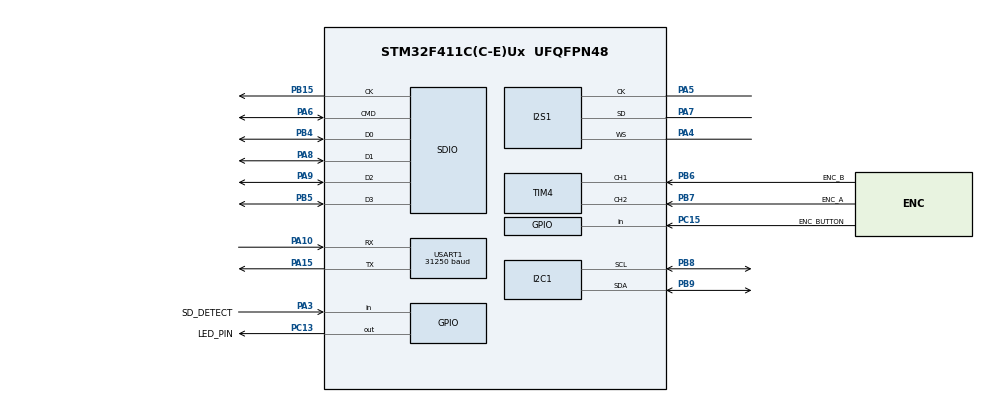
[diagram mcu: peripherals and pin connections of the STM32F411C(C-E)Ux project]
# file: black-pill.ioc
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Dma.I2C1_TX.1.Direction=DMA_MEMORY_TO_PERIPH
Dma.I2C1_TX.1.FIFOMode=DMA_FIFOMODE_DISABLE
Dma.I2C1_TX.1.Instance=DMA1_Stream1
Dma.I2C1_TX.1.MemDataAlignment=DMA_MDATAALIGN_BYTE
Dma.I2C1_TX.1.MemInc=DMA_MINC_ENABLE
Dma.I2C1_TX.1.Mode=DMA_NORMAL
Dma.I2C1_TX.1.PeriphDataAlignment=DMA_PDATAALIGN_BYTE
Dma.I2C1_TX.1.PeriphInc=DMA_PINC_DISABLE
Dma.I2C1_TX.1.Priority=DMA_PRIORITY_LOW
Dma.Request0=SPI1_TX
Dma.Request1=I2C1_TX
Dma.Request2=SDIO_RX
Dma.Request3=SDIO_TX
Dma.SDIO_RX.2.Direction=DMA_PERIPH_TO_MEMORY
Dma.SDIO_RX.2.FIFOMode=DMA_FIFOMODE_ENABLE
Dma.SDIO_RX.2.FIFOThreshold=DMA_FIFO_THRESHOLD_FULL
Dma.SDIO_RX.2.Instance=DMA2_Stream3
Dma.SDIO_RX.2.MemBurst=DMA_MBURST_INC4
Dma.SDIO_RX.2.MemDataAlignment=DMA_MDATAALIGN_WORD
Dma.SDIO_RX.2.MemInc=DMA_MINC_ENABLE
Dma.SDIO_RX.2.Mode=DMA_PFCTRL
Dma.SDIO_RX.2.PeriphBurst=DMA_PBURST_INC4
Dma.SDIO_RX.2.PeriphDataAlignment=DMA_PDATAALIGN_WORD
Dma.SDIO_RX.2.PeriphInc=DMA_PINC_DISABLE
Dma.SDIO_RX.2.Priority=DMA_PRIORITY_VERY_HIGH
Dma.SDIO_TX.3.Direction=DMA_MEMORY_TO_PERIPH
Dma.SDIO_TX.3.FIFOMode=DMA_FIFOMODE_ENABLE
Dma.SDIO_TX.3.FIFOThreshold=DMA_FIFO_THRESHOLD_FULL
Dma.SDIO_TX.3.Instance=DMA2_Stream6
Dma.SDIO_TX.3.MemBurst=DMA_MBURST_INC4
Dma.SDIO_TX.3.MemDataAlignment=DMA_MDATAALIGN_WORD
Dma.SDIO_TX.3.MemInc=DMA_MINC_ENABLE
Dma.SDIO_TX.3.Mode=DMA_PFCTRL
Dma.SDIO_TX.3.PeriphBurst=DMA_PBURST_INC4
Dma.SDIO_TX.3.PeriphDataAlignment=DMA_PDATAALIGN_WORD
Dma.SDIO_TX.3.PeriphInc=DMA_PINC_DISABLE
Dma.SDIO_TX.3.Priority=DMA_PRIORITY_VERY_HIGH
Dma.SPI1_TX.0.Direction=DMA_MEMORY_TO_PERIPH
Dma.SPI1_TX.0.FIFOMode=DMA_FIFOMODE_DISABLE
Dma.SPI1_TX.0.Instance=DMA2_Stream2
Dma.SPI1_TX.0.MemDataAlignment=DMA_MDATAALIGN_HALFWORD
Dma.SPI1_TX.0.MemInc=DMA_MINC_ENABLE
Dma.SPI1_TX.0.Mode=DMA_CIRCULAR
Dma.SPI1_TX.0.PeriphDataAlignment=DMA_PDATAALIGN_HALFWORD
Dma.SPI1_TX.0.PeriphInc=DMA_PINC_DISABLE
Dma.SPI1_TX.0.Priority=DMA_PRIORITY_HIGH
FATFS.BSP.number=1
FATFS.USE_DMA_CODE_SD=1
FATFS._CODE_PAGE=850
FATFS._FS_LOCK=0
FATFS._FS_NORTC=0
FATFS._FS_REENTRANT=1
FATFS._USE_LFN=3
FATFS._USE_MKFS=0
FATFS._USE_MUTEX=1
FATFS._USE_STRFUNC=0
FATFS0.BSP.STBoard=false
FATFS0.BSP.api=Unknown
FATFS0.BSP.i2caddr=0
FATFS0.BSP.instance=PA3
FATFS0.BSP.ip=GPIO
FATFS0.BSP.mode=Input
FATFS0.BSP.name=Detect_SDIO
FATFS0.BSP.solution=PA3
FREERTOS.Tasks01=defaultTask,24,128,StartDefaultTask,Default,NULL,Dynamic,NULL,NULL
FREERTOS.configENABLE_FPU=1
I2C1.I2C_Mode=I2C_Fast
I2S1.AudioFreq=I2S_AUDIOFREQ_44K
I2S1.CPOL=I2S_CPOL_HIGH
I2S1.ErrorAudioFreq=0.22 %
I2S1.FullDuplexMode=I2S_FULLDUPLEXMODE_DISABLE
I2S1.Instance=SPI$Index
I2S1.RealAudioFreq=44.1 KHz
I2S1.Standard=I2S_STANDARD_MSB
I2S1.VirtualMode=I2S_MODE_MASTER
Mcu.Family=STM32F4
Mcu.Name=STM32F411C(C-E)Ux
Mcu.Package=UFQFPN48
NVIC.DMA1_Stream1_IRQn=true\:5\:0\:false\:false\:true\:true\:false\:true
NVIC.DMA2_Stream2_IRQn=true\:5\:0\:true\:false\:true\:true\:false\:true
NVIC.DMA2_Stream3_IRQn=true\:5\:0\:true\:false\:true\:true\:false\:true
NVIC.DMA2_Stream6_IRQn=true\:5\:0\:true\:false\:true\:true\:false\:true
NVIC.I2C1_ER_IRQn=true\:5\:0\:true\:false\:true\:true\:true\:true
NVIC.I2C1_EV_IRQn=true\:5\:0\:true\:false\:true\:true\:true\:true
NVIC.PriorityGroup=NVIC_PRIORITYGROUP_4
NVIC.SDIO_IRQn=true\:5\:0\:true\:false\:true\:true\:true\:true
NVIC.TIM1_UP_TIM10_IRQn=true\:15\:0\:false\:false\:true\:false\:false\:true
NVIC.TimeBase=TIM1_UP_TIM10_IRQn
NVIC.TimeBaseIP=TIM10
PA10.Mode=Asynchronous
PA10.Signal=USART1_RX
PA13.Mode=Serial_Wire
PA13.Signal=SYS_JTMS-SWDIO
PA14.Mode=Serial_Wire
PA14.Signal=SYS_JTCK-SWCLK
PA15.Mode=Asynchronous
PA15.Signal=USART1_TX
PA3.GPIO_Label=SD_DETECT
PA3.GPIO_PuPd=GPIO_PULLUP
PA3.Signal=GPIO_Input
PA4.Mode=Half_Duplex_Master
PA4.Signal=I2S1_WS
PA5.Mode=Half_Duplex_Master
PA5.Signal=I2S1_CK
PA6.GPIO_PuPd=GPIO_PULLUP
PA6.Mode=SD_4_bits_Wide_bus
PA6.Signal=SDIO_CMD
PA7.Mode=Half_Duplex_Master
PA7.Signal=I2S1_SD
PA8.GPIO_PuPd=GPIO_PULLUP
PA8.Mode=SD_4_bits_Wide_bus
PA8.Signal=SDIO_D1
PA9.GPIO_PuPd=GPIO_PULLUP
PA9.Mode=SD_4_bits_Wide_bus
PA9.Signal=SDIO_D2
PB15.GPIO_PuPd=GPIO_PULLUP
PB15.Mode=SD_4_bits_Wide_bus
PB15.Signal=SDIO_CK
PB4.GPIO_PuPd=GPIO_PULLUP
PB4.Mode=SD_4_bits_Wide_bus
PB4.Signal=SDIO_D0
PB5.GPIO_PuPd=GPIO_PULLUP
PB5.Mode=SD_4_bits_Wide_bus
PB5.Signal=SDIO_D3
PB6.GPIO_Label=ENC_B
PB6.GPIO_PuPd=GPIO_PULLUP
PB6.Signal=S_TIM4_CH1
PB7.GPIO_Label=ENC_A
PB7.GPIO_PuPd=GPIO_PULLUP
PB7.Signal=S_TIM4_CH2
PB8.GPIO_Pu=GPIO_PULLUP
PB8.Mode=I2C
PB8.Signal=I2C1_SCL
PB9.GPIO_Pu=GPIO_PULLUP
PB9.Mode=I2C
PB9.Signal=I2C1_SDA
PC13-ANTI_TAMP.GPIO_Label=LED_PIN
PC13-ANTI_TAMP.Signal=GPIO_Output
PC15-OSC32_OUT.GPIO_Label=ENC_BUTTON
PC15-OSC32_OUT.GPIO_PuPd=GPIO_PULLUP
PC15-OSC32_OUT.Signal=GPIO_Input
PH0\ -\ OSC_IN.Mode=HSE-External-Oscillator
PH0\ -\ OSC_IN.Signal=RCC_OSC_IN
PH1\ -\ OSC_OUT.Mode=HSE-External-Oscillator
PH1\ -\ OSC_OUT.Signal=RCC_OSC_OUT
ProjectManager.HeapSize=0x2000
ProjectManager.StackSize=0x4000
ProjectManager.TargetToolchain=Makefile
RCC.48MHZClocksFreq_Value=48000000
RCC.AHBFreq_Value=96000000
RCC.APB1CLKDivider=RCC_HCLK_DIV2
RCC.APB1Freq_Value=48000000
RCC.APB1TimFreq_Value=96000000
RCC.APB2Freq_Value=96000000
RCC.APB2TimFreq_Value=96000000
RCC.CortexFreq_Value=96000000
RCC.HCLKFreq_Value=96000000
RCC.HSE_VALUE=25000000
RCC.HSI_VALUE=16000000
RCC.LSE_VALUE=32768
RCC.PLLI2SM=25
RCC.PLLI2SN=302
RCC.PLLM=25
RCC.PLLSourceVirtual=RCC_PLLSOURCE_HSE
RCC.SYSCLKFreq_VALUE=96000000
RCC.SYSCLKSource=RCC_SYSCLKSOURCE_PLLCLK
RCC.VCOOutputFreq_Value=192000000
SDIO.ClockDiv=0
SH.S_TIM4_CH1.0=TIM4_CH1,Encoder_Interface
SH.S_TIM4_CH2.0=TIM4_CH2,Encoder_Interface
TIM4.EncoderMode=TIM_ENCODERMODE_TI12
USART1.BaudRate=31250
USART1.VirtualMode=VM_ASYNC
VP_FATFS_VS_SDIO.Mode=SDIO
VP_FREERTOS_VS_CMSIS_V2.Mode=CMSIS_V2
VP_SYS_VS_tim10.Mode=TIM10
board=custom

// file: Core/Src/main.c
/* USER CODE BEGIN Header */
/**
  ******************************************************************************
  * @file           : main.c
  * @brief          : Main program body
  ******************************************************************************
  * @attention
  *
  * <h2><center>&copy; Copyright (c) 2021 STMicroelectronics.
  * All rights reserved.</center></h2>
  *
  * This software component is licensed by ST under BSD 3-Clause license,
  * the "License"; You may not use this file except in compliance with the
  * License. You may obtain a copy of the License at:
  *                        opensource.org/licenses/BSD-3-Clause
  *
  ******************************************************************************
  */
/* USER CODE END Header */
#include "main.h"
#include "cmsis_os.h"
#include "fatfs.h"

/* USER CODE BEGIN Includes */
#include "app.h"

const osThreadAttr_t app_main_attributes = {
  .name = "app_main",
  .stack_size = 8096,
  .priority = osPriorityNormal,
};
/* USER CODE END Includes */

I2C_HandleTypeDef hi2c1;
DMA_HandleTypeDef hdma_i2c1_tx;

I2S_HandleTypeDef hi2s1;
DMA_HandleTypeDef hdma_spi1_tx;

SD_HandleTypeDef hsd;
DMA_HandleTypeDef hdma_sdio_rx;
DMA_HandleTypeDef hdma_sdio_tx;

TIM_HandleTypeDef htim4;

/* Definitions for defaultTask */
osThreadId_t defaultTaskHandle;
const osThreadAttr_t defaultTask_attributes = {
  .name = "defaultTask",
  .stack_size = 128 * 4,
  .priority = (osPriority_t) osPriorityNormal,
};

void SystemClock_Config(void);
void PeriphCommonClock_Config(void);
static void MX_GPIO_Init(void);
static void MX_USART1_UART_Init(void);
static void MX_I2S1_Init(void);
static void MX_SDIO_SD_Init(void);
static void MX_DMA_Init(void);
static void MX_I2C1_Init(void);
static void MX_TIM4_Init(void);
void StartDefaultTask(void *argument);

int main(void)
{
  /* USER CODE BEGIN 1 */

  /*HAL_Init();
  SystemClock_Config();
  LL_AHB1_GRP1_EnableClock(LL_AHB1_GRP1_PERIPH_GPIOA);
  LL_AHB1_GRP1_EnableClock(LL_AHB1_GRP1_PERIPH_GPIOB);
  LL_AHB1_GRP1_EnableClock(LL_AHB1_GRP1_PERIPH_GPIOC);
  LL_AHB1_GRP1_EnableClock(LL_AHB1_GRP1_PERIPH_GPIOH);
  LL_APB2_GRP1_EnableClock(LL_APB2_GRP1_PERIPH_USART1);
  LL_APB1_GRP1_EnableClock(LL_APB1_GRP1_PERIPH_USART2);
  app_main();
  return 0;*/

  /* USER CODE END 1 */

  /* MCU Configuration--------------------------------------------------------*/

  /* Reset of all peripherals, Initializes the Flash interface and the Systick. */
  HAL_Init();

  /* Configure the system clock */
  SystemClock_Config();

/* Configure the peripherals common clocks */
  PeriphCommonClock_Config();

  /* USER CODE BEGIN SysInit */

  // must be called before initializing dma-capable peripherals
  MX_DMA_Init();

  /* USER CODE END SysInit */

  /* Initialize all configured peripherals */
  MX_GPIO_Init();
  MX_USART1_UART_Init();
  MX_I2S1_Init();
  MX_SDIO_SD_Init();
  MX_DMA_Init();
  MX_FATFS_Init();
  MX_I2C1_Init();
  MX_TIM4_Init();
  /* USER CODE BEGIN 2 */
  osKernelInitialize();
  osThreadNew(app_main, NULL, &app_main_attributes);
  osKernelStart();

  while(1){

  }
  /* USER CODE END 2 */

  /* Init scheduler */
  osKernelInitialize();

  /* Create the thread(s) */
  /* creation of defaultTask */
  defaultTaskHandle = osThreadNew(StartDefaultTask, NULL, &defaultTask_attributes);

  /* Start scheduler */
  osKernelStart();

  /* We should never get here as control is now taken by the scheduler */
  /* Infinite loop */
  while (1)
  {

  }
}

void SystemClock_Config(void)
{
  LL_FLASH_SetLatency(LL_FLASH_LATENCY_3);
  while(LL_FLASH_GetLatency()!= LL_FLASH_LATENCY_3)
  {
  }
  LL_PWR_SetRegulVoltageScaling(LL_PWR_REGU_VOLTAGE_SCALE1);
  LL_RCC_HSE_Enable();

   /* Wait till HSE is ready */
  while(LL_RCC_HSE_IsReady() != 1)
  {

  }
  LL_RCC_PLL_ConfigDomain_SYS(LL_RCC_PLLSOURCE_HSE, LL_RCC_PLLM_DIV_25, 192, LL_RCC_PLLP_DIV_2);
  LL_RCC_PLL_ConfigDomain_48M(LL_RCC_PLLSOURCE_HSE, LL_RCC_PLLM_DIV_25, 192, LL_RCC_PLLQ_DIV_4);
  LL_RCC_PLL_Enable();

   /* Wait till PLL is ready */
  while(LL_RCC_PLL_IsReady() != 1)
  {

  }
  LL_RCC_SetAHBPrescaler(LL_RCC_SYSCLK_DIV_1);
  LL_RCC_SetAPB1Prescaler(LL_RCC_APB1_DIV_2);
  LL_RCC_SetAPB2Prescaler(LL_RCC_APB2_DIV_1);
  LL_RCC_SetSysClkSource(LL_RCC_SYS_CLKSOURCE_PLL);

   /* Wait till System clock is ready */
  while(LL_RCC_GetSysClkSource() != LL_RCC_SYS_CLKSOURCE_STATUS_PLL)
  {

  }
  LL_SetSystemCoreClock(96000000);

   /* Update the time base */
  if (HAL_InitTick (TICK_INT_PRIORITY) != HAL_OK)
  {
    Error_Handler();
  }
  LL_RCC_SetTIMPrescaler(LL_RCC_TIM_PRESCALER_TWICE);
}

void PeriphCommonClock_Config(void)
{
  LL_RCC_PLLI2S_ConfigDomain_I2S(LL_RCC_PLLSOURCE_HSE, LL_RCC_PLLI2SM_DIV_25, 302, LL_RCC_PLLI2SR_DIV_2);
  LL_RCC_PLLI2S_Enable();

   /* Wait till PLL is ready */
  while(LL_RCC_PLLI2S_IsReady() != 1)
  {

  }
}

static void MX_I2C1_Init(void)
{

  hi2c1.Instance = I2C1;
  hi2c1.Init.ClockSpeed = 400000;
  hi2c1.Init.DutyCycle = I2C_DUTYCYCLE_2;
  hi2c1.Init.OwnAddress1 = 0;
  hi2c1.Init.AddressingMode = I2C_ADDRESSINGMODE_7BIT;
  hi2c1.Init.DualAddressMode = I2C_DUALADDRESS_DISABLE;
  hi2c1.Init.OwnAddress2 = 0;
  hi2c1.Init.GeneralCallMode = I2C_GENERALCALL_DISABLE;
  hi2c1.Init.NoStretchMode = I2C_NOSTRETCH_DISABLE;
  if (HAL_I2C_Init(&hi2c1) != HAL_OK)
  {
    Error_Handler();
  }

}

static void MX_I2S1_Init(void)
{

  hi2s1.Instance = SPI1;
  hi2s1.Init.Mode = I2S_MODE_MASTER_TX;
  hi2s1.Init.Standard = I2S_STANDARD_MSB;
  hi2s1.Init.DataFormat = I2S_DATAFORMAT_16B;
  hi2s1.Init.MCLKOutput = I2S_MCLKOUTPUT_DISABLE;
  hi2s1.Init.AudioFreq = I2S_AUDIOFREQ_44K;
  hi2s1.Init.CPOL = I2S_CPOL_HIGH;
  hi2s1.Init.ClockSource = I2S_CLOCK_PLL;
  hi2s1.Init.FullDuplexMode = I2S_FULLDUPLEXMODE_DISABLE;
  if (HAL_I2S_Init(&hi2s1) != HAL_OK)
  {
    Error_Handler();
  }

}

static void MX_SDIO_SD_Init(void)
{

  hsd.Instance = SDIO;
  hsd.Init.ClockEdge = SDIO_CLOCK_EDGE_RISING;
  hsd.Init.ClockBypass = SDIO_CLOCK_BYPASS_DISABLE;
  hsd.Init.ClockPowerSave = SDIO_CLOCK_POWER_SAVE_DISABLE;
  hsd.Init.BusWide = SDIO_BUS_WIDE_1B;
  hsd.Init.HardwareFlowControl = SDIO_HARDWARE_FLOW_CONTROL_DISABLE;
  hsd.Init.ClockDiv = 0;

}

static void MX_TIM4_Init(void)
{

  TIM_Encoder_InitTypeDef sConfig = {0};
  TIM_MasterConfigTypeDef sMasterConfig = {0};

  htim4.Instance = TIM4;
  htim4.Init.Prescaler = 0;
  htim4.Init.CounterMode = TIM_COUNTERMODE_UP;
  htim4.Init.Period = 65535;
  htim4.Init.ClockDivision = TIM_CLOCKDIVISION_DIV1;
  htim4.Init.AutoReloadPreload = TIM_AUTORELOAD_PRELOAD_DISABLE;
  sConfig.EncoderMode = TIM_ENCODERMODE_TI12;
  sConfig.IC1Polarity = TIM_ICPOLARITY_RISING;
  sConfig.IC1Selection = TIM_ICSELECTION_DIRECTTI;
  sConfig.IC1Prescaler = TIM_ICPSC_DIV1;
  sConfig.IC1Filter = 0;
  sConfig.IC2Polarity = TIM_ICPOLARITY_RISING;
  sConfig.IC2Selection = TIM_ICSELECTION_DIRECTTI;
  sConfig.IC2Prescaler = TIM_ICPSC_DIV1;
  sConfig.IC2Filter = 0;
  if (HAL_TIM_Encoder_Init(&htim4, &sConfig) != HAL_OK)
  {
    Error_Handler();
  }
  sMasterConfig.MasterOutputTrigger = TIM_TRGO_RESET;
  sMasterConfig.MasterSlaveMode = TIM_MASTERSLAVEMODE_DISABLE;
  if (HAL_TIMEx_MasterConfigSynchronization(&htim4, &sMasterConfig) != HAL_OK)
  {
    Error_Handler();
  }

}

static void MX_USART1_UART_Init(void)
{

  LL_USART_InitTypeDef USART_InitStruct = {0};

  LL_GPIO_InitTypeDef GPIO_InitStruct = {0};

  /* Peripheral clock enable */
  LL_APB2_GRP1_EnableClock(LL_APB2_GRP1_PERIPH_USART1);

  LL_AHB1_GRP1_EnableClock(LL_AHB1_GRP1_PERIPH_GPIOA);
  /**USART1 GPIO Configuration
  PA10   ------> USART1_RX
  PA15   ------> USART1_TX
  */
  GPIO_InitStruct.Pin = LL_GPIO_PIN_10|LL_GPIO_PIN_15;
  GPIO_InitStruct.Mode = LL_GPIO_MODE_ALTERNATE;
  GPIO_InitStruct.Speed = LL_GPIO_SPEED_FREQ_VERY_HIGH;
  GPIO_InitStruct.OutputType = LL_GPIO_OUTPUT_PUSHPULL;
  GPIO_InitStruct.Pull = LL_GPIO_PULL_NO;
  GPIO_InitStruct.Alternate = LL_GPIO_AF_7;
  LL_GPIO_Init(GPIOA, &GPIO_InitStruct);

  /* USER CODE BEGIN USART1_Init 1 */
  return;
  /* USER CODE END USART1_Init 1 */
  USART_InitStruct.BaudRate = 31250;
  USART_InitStruct.DataWidth = LL_USART_DATAWIDTH_8B;
  USART_InitStruct.StopBits = LL_USART_STOPBITS_1;
  USART_InitStruct.Parity = LL_USART_PARITY_NONE;
  USART_InitStruct.TransferDirection = LL_USART_DIRECTION_TX_RX;
  USART_InitStruct.HardwareFlowControl = LL_USART_HWCONTROL_NONE;
  USART_InitStruct.OverSampling = LL_USART_OVERSAMPLING_16;
  LL_USART_Init(USART1, &USART_InitStruct);
  LL_USART_ConfigAsyncMode(USART1);
  LL_USART_Enable(USART1);

}

static void MX_DMA_Init(void)
{

  /* DMA controller clock enable */
  __HAL_RCC_DMA2_CLK_ENABLE();
  __HAL_RCC_DMA1_CLK_ENABLE();

  /* DMA interrupt init */
  /* DMA1_Stream1_IRQn interrupt configuration */
  HAL_NVIC_SetPriority(DMA1_Stream1_IRQn, 5, 0);
  HAL_NVIC_EnableIRQ(DMA1_Stream1_IRQn);
  /* DMA2_Stream2_IRQn interrupt configuration */
  HAL_NVIC_SetPriority(DMA2_Stream2_IRQn, 5, 0);
  HAL_NVIC_EnableIRQ(DMA2_Stream2_IRQn);
  /* DMA2_Stream3_IRQn interrupt configuration */
  HAL_NVIC_SetPriority(DMA2_Stream3_IRQn, 5, 0);
  HAL_NVIC_EnableIRQ(DMA2_Stream3_IRQn);
  /* DMA2_Stream6_IRQn interrupt configuration */
  HAL_NVIC_SetPriority(DMA2_Stream6_IRQn, 5, 0);
  HAL_NVIC_EnableIRQ(DMA2_Stream6_IRQn);

}

static void MX_GPIO_Init(void)
{
  LL_GPIO_InitTypeDef GPIO_InitStruct = {0};

  /* GPIO Ports Clock Enable */
  LL_AHB1_GRP1_EnableClock(LL_AHB1_GRP1_PERIPH_GPIOC);
  LL_AHB1_GRP1_EnableClock(LL_AHB1_GRP1_PERIPH_GPIOH);
  LL_AHB1_GRP1_EnableClock(LL_AHB1_GRP1_PERIPH_GPIOA);
  LL_AHB1_GRP1_EnableClock(LL_AHB1_GRP1_PERIPH_GPIOB);

  /**/
  LL_GPIO_ResetOutputPin(LED_PIN_GPIO_Port, LED_PIN_Pin);

  /**/
  GPIO_InitStruct.Pin = LED_PIN_Pin;
  GPIO_InitStruct.Mode = LL_GPIO_MODE_OUTPUT;
  GPIO_InitStruct.Speed = LL_GPIO_SPEED_FREQ_LOW;
  GPIO_InitStruct.OutputType = LL_GPIO_OUTPUT_PUSHPULL;
  GPIO_InitStruct.Pull = LL_GPIO_PULL_NO;
  LL_GPIO_Init(LED_PIN_GPIO_Port, &GPIO_InitStruct);

  /**/
  GPIO_InitStruct.Pin = ENC_BUTTON_Pin;
  GPIO_InitStruct.Mode = LL_GPIO_MODE_INPUT;
  GPIO_InitStruct.Pull = LL_GPIO_PULL_UP;
  LL_GPIO_Init(ENC_BUTTON_GPIO_Port, &GPIO_InitStruct);

  /**/
  GPIO_InitStruct.Pin = SD_DETECT_Pin;
  GPIO_InitStruct.Mode = LL_GPIO_MODE_INPUT;
  GPIO_InitStruct.Pull = LL_GPIO_PULL_UP;
  LL_GPIO_Init(SD_DETECT_GPIO_Port, &GPIO_InitStruct);

}

void StartDefaultTask(void *argument)
{
  for(;;)
  {
    osDelay(1);
  }
}

void HAL_TIM_PeriodElapsedCallback(TIM_HandleTypeDef *htim)
{
  if (htim->Instance == TIM10) {
    HAL_IncTick();
  }
}

void Error_Handler(void)
{
  /* USER CODE BEGIN Error_Handler_Debug */
  /* User can add his own implementation to report the HAL error return state */
  __disable_irq();
  asm("bkpt 1");
  while (1)
  {
  }
  /* USER CODE END Error_Handler_Debug */
}
